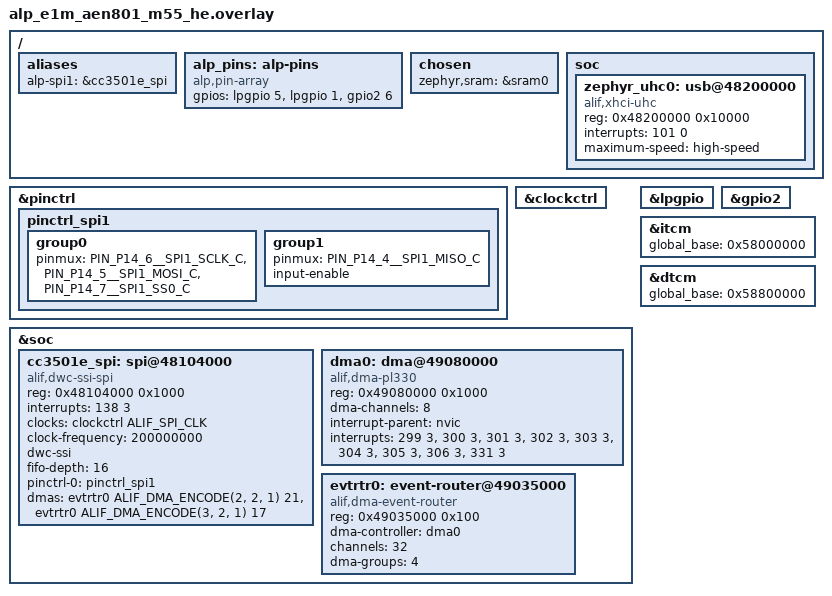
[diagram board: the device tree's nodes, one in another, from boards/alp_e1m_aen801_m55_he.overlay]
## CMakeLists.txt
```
# Copyright (c) 2026 Alp Lab AB
# SPDX-License-Identifier: Apache-2.0
cmake_minimum_required(VERSION 3.20.0)
find_package(Zephyr REQUIRED HINTS $ENV{ZEPHYR_BASE})
project(aen_usb_firstlight)
target_sources(app PRIVATE src/main.c src/cc3501e_bridge.c)
```

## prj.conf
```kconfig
CONFIG_ALP_SDK=y
CONFIG_MAIN_STACK_SIZE=4096
CONFIG_UHC_DRIVER=y
CONFIG_DCACHE=n
CONFIG_SPI=y
CONFIG_GPIO=y
CONFIG_ALP_SDK_CHIP_CC3501E=y
CONFIG_DMA=y
CONFIG_DMA_PL330_ALIF=y
CONFIG_DMA_ALIF_EVENT_ROUTER=y
CONFIG_SPI_DW_ALIF_USE_DMA=y
CONFIG_SPI_DW_ALIF_DMA_MIN_LEN=64
```

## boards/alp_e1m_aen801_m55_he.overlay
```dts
/*
 * Copyright (c) 2026 Alp Lab AB
 * SPDX-License-Identifier: Apache-2.0
 *
 * Inter-chip wiring for the CC3501E bring-up on the E1M-AEN801 (Alif
 * Ensemble E8, M55-HE).  Declares the SoM-internal Alif<->CC3501E link:
 * the SPI1 master bus + the two host-driven control nets, all from
 * metadata/e1m_modules/aen/inter-chip.tsv:
 *
 *   SPI1.SCK  P14_6   SPI1.MOSI P14_5   SPI1.MISO P14_4   (-> CC3501E GPIO_27/28/29)
 *   WIFI_EN   P15_5 (lpgpio 5)          E_WIFI.NRST P15_1_FLEX (lpgpio 1)
 *
 * "P15" is the Alif low-power GPIO island (lpgpio @ 0x42002000); the
 * _FLEX pads are its pins.  P14 is a main-domain port used here purely as
 * the SPI1 function via pinctrl, so no gpio14 controller node is needed.
 *
 * BENCH-UNVERIFIED.  Like the rest of the alp-sdk Alif peripheral layer
 * (zephyr/dts/alif/ensemble_e8_peripherals.dtsi), the addresses/IRQs are
 * transcribed from the Apache-2.0 alifsemi/zephyr_alif fork + the AE822
 * TRM and have NOT been validated on silicon.  The SPI1 pinctrl macros are
 * RESOLVED against zephyr/dt-bindings/pinctrl/alif-ensemble-pinctrl.h
 * (SPI1 on P14_4/5/6 = alt-2, the `_C` suffix) and the LP-GPIO mux is the
 * reset default (alt-0 = LPGPIO); the one remaining genuine unknown is the
 * SPI1 IRQ number (upstream Zephyr declares no SPI node, so it is not in
 * the build tree) -- confirm it against the AE822 TRM before relying on
 * the interrupt-driven path on silicon.
 */

#include <zephyr/dt-bindings/pinctrl/alif-ensemble-pinctrl.h>
#include <zephyr/dt-bindings/gpio/gpio.h>
#include <zephyr/dt-bindings/dma/alif_dma_event_router.h>

&pinctrl {
	/*
	 * SPI1 master on P14_6 (SCK) / P14_5 (MOSI) / P14_4 (MISO).
	 *
	 * RESOLVED against alif-ensemble-pinctrl.h: the SPI1 functions on these
	 * three pads are alt-2, named with the `_C` suffix
	 * (PIN_P14_6__SPI1_SCLK_C = ALIF_PINMUX(14, 6, 2), etc.).  input-enable
	 * on MISO so the pad can sense the slave's drive (the same read-enable
	 * requirement the I2C pads need on this SoC).
	 */
	pinctrl_spi1: pinctrl_spi1 {
		group0 {
			/* Hardware SS0 chip-select (P14_7 = SPI1_SS0_C) -- dwc-ssi master
			 * drives SS0 per transfer to frame the CC3501E slave. */
			pinmux = <PIN_P14_6__SPI1_SCLK_C>, <PIN_P14_5__SPI1_MOSI_C>,
				 <PIN_P14_7__SPI1_SS0_C>;
		};
		group1 {
			pinmux = <PIN_P14_4__SPI1_MISO_C>;
			input-enable;
		};
	};
};

/*
 * DWC_ssi SPI1 (AHB) -- the on-SoM CC3501E inter-chip link.  Deliberately
 * NOT in ensemble_e8_peripherals.dtsi (that dtsi declares only the
 * customer-facing edge SPI0); this is the SoM-internal Wi-Fi link, so it
 * lives in the consuming app's overlay.  Same driver + flags as spi0
 * (compatible "alif,dwc-ssi-spi", dwc-ssi layout, fifo-depth 16,
 * frequency-only ALIF_SPI_CLK).
 *
 * reg 0x48104000 = SPI1 base (spi0 is 0x48103000, +0x1000/instance).
 * BENCH-TBD: interrupts = <138 3> follows the consecutive pattern from
 * spi0's IRQ 137 -- confirm SPI1_IRQ against the fork's e1.dtsi / TRM.
 *
 * No cs-gpios / HW-SS: this rev runs CS-less 3-wire (the host driver
 * clocks fixed-count lockstep transfers; see chips/cc3501e/cc3501e.c).
 */
&clockctrl {
	status = "okay";
};

&soc {
	cc3501e_spi: spi@48104000 {
		compatible = "alif,dwc-ssi-spi";
		#address-cells = <1>;
		#size-cells = <0>;
		reg = <0x48104000 0x1000>;
		interrupts = <138 3>;          /* BENCH-TBD: confirm SPI1 IRQ */
		clocks = <&clockctrl ALIF_SPI_CLK>;
		/*
		 * ROOT-CAUSE FIX 2026-06-16: spi_dw_alif's configure takes the
		 * clock-control path when no clock-frequency is set, and that path
		 * fails (-EINVAL) for the gateless dummy ALIF_SPI_CLK -> every
		 * transceive returned ALP_ERR_INVAL with zero SCLK (witness fail_step=1,
		 * zerr=-EINVAL). Providing the SSI input clock here makes the driver
		 * use it directly and skip the failing clock-control path. SYST_HCLK =
		 * AHB = 400 MHz (E8 HWRM); BAUDR = 400M/freq_hz (=50 for an 8 MHz SCLK).
		 */
		clock-frequency = <200000000>; /* real SSI functional clock (was mis-set 400M; proven via BAUDR scaling) */
		dwc-ssi;
		fifo-depth = <16>;
		pinctrl-0 = <&pinctrl_spi1>;
		pinctrl-names = "default";
		status = "okay";
	};
};

/*
 * Enable the LP GPIO island so WIFI_EN (P15_5) and E_WIFI.NRST
 * (P15_1_FLEX) are drivable as outputs.  gpio_dw needs no clocks/pinctrl
 * on the controller, and the pad->GPIO mux needs no pinctrl group either:
 * RESOLVED against alif-ensemble-pinctrl.h -- P15_1/P15_5 function 0 (the
 * reset default) IS LPGPIO (PIN_P15_x__LPGPIO = ALIF_PINMUX(15, x, 0)).
 */
&lpgpio {
	status = "okay";
};

/*
 * gpio2 for the host-IRQ/READY input (CC35 GPIO17 -> Alif P2_6, alp_pins[2]).
 * P2_6's reset-default mux is function 0 = GPIO (PIN_P2_6__GPIO), so no pinctrl
 * group is needed; gpio_dw defaults the pin to input, which the app confirms via
 * alp_gpio_configure(INPUT).  The READY line lets the host gate reply phases on
 * the slave's actual re-arm instead of a fixed settle gap. */
&gpio2 {
	status = "okay";
};

/*
 * Host-side peripheral DMA for continuous SPI streams over the CC3501E bridge.
 * SPI1 is a MAIN-domain peripheral, so per the AE822 DFP soc_dma_map (SPI1_DMA=0,
 * group 2, TX req 21 / RX req 17) it routes through the SYSTOP DMA0 via its event
 * router evtrtr0 (4 groups -> group 2 valid) -- NOT the M55-HE-local DMA2/evtrtr2
 * (1 group, for LP peripherals; wiring SPI1 there leaves the channel Waiting-For-
 * Peripheral forever -- SPI1's request line isn't on the HE router).  DMA0's clock
 * is SYSTOP (already on -- the app drives SPI1/GPIO in the same region); its
 * PL330 boot-manager security latch (CLKCTRL_PER_MST) is in dma_alif_boot_latch.c.
 * The fork PL330 driver statically allocates the per-channel ucode + remaps it via
 * local_to_global(), so no external `microcode` prop is needed.  IRQs 299..306 =
 * the 8 DMA0 channel-done lines, 331 = abort (AE822 DFP rtss_he).
 */
&soc {
	dma0: dma@49080000 {
		compatible = "alif,dma-pl330";
		reg = <0x49080000 0x1000>;
		#dma-cells = <2>;
		dma-channels = <8>;
		interrupt-parent = <&nvic>;
		interrupts = <299 3>, <300 3>, <301 3>, <302 3>, <303 3>,
			     <304 3>, <305 3>, <306 3>, <331 3>;
		interrupt-names = "channel0", "channel1", "channel2", "channel3",
				  "channel4", "channel5", "channel6", "channel7", "abort";
		status = "okay";
	};

	evtrtr0: event-router@49035000 {
		compatible = "alif,dma-event-router";
		reg = <0x49035000 0x100>;
		dma-controller = <&dma0>;
		channels = <32>;
		dma-groups = <4>;  /* SYSTOP router: 4 ACK_TYPE groups (0-3); SPI1 uses group 2 */
		#dma-cells = <2>;
		status = "okay";
	};
};

/*
 * Route the bridge SPI1 through evtrtr0 to DMA0.  Cell encoding
 * (ALIF_DMA_ENCODE(channel, dma_group, handshake), periph_req):
 *   TX = PL330 ch2, evtrtr group 2, handshake on, SPI1 TX periph req 21
 *   RX = PL330 ch3, evtrtr group 2, handshake on, SPI1 RX periph req 17
 * (AE822 DFP soc_dma_map.h: SPI1 group 2, TX 21 / RX 17.)
 */
&cc3501e_spi {
	dmas = <&evtrtr0 ALIF_DMA_ENCODE(2, 2, 1) 21>,
	       <&evtrtr0 ALIF_DMA_ENCODE(3, 2, 1) 17>;
	dma-names = "txdma", "rxdma";
};

/ {
	aliases {
		/* bus_id 1 in alp_spi_open() -> this controller. */
		alp-spi1 = &cc3501e_spi;
	};

	/*
	 * Compact 2-entry control array for the SoM-internal CC3501E nets, in
	 * the order the app's CC3501E_PIN_* indices expect.  These are NOT E1M
	 * edge pads, so this bring-up app intentionally does NOT use the
	 * 52-slot positional E1M map; a production board file appends such
	 * SoM-internal control nets after the E1M pad slots.
	 */
	alp_pins: alp-pins {
		compatible = "alp,pin-array";
		gpios = <&lpgpio 5 GPIO_ACTIVE_HIGH>,   /* [0] WIFI_EN     (P15_5)      */
			<&lpgpio 1 GPIO_ACTIVE_HIGH>,   /* [1] E_WIFI.NRST (P15_1_FLEX) */
			<&gpio2 6 GPIO_ACTIVE_HIGH>;    /* [2] host-IRQ/READY (P2_6 <- CC35 GPIO17) */
	};
};

/*
 * Global-bus aliases of the M55-HE TCMs, needed by hal_alif soc_memory_map.h
 * local_to_global() -- the PL330 (AXI master) reaches TCM-resident buffers only
 * via these global windows.  Values from the AE822 M55-HE map (sdk-alif fork
 * ensemble_rtss_he.dtsi): ITCM 0x0->0x58000000, DTCM 0x20000000->0x58800000.
 * (DMA stream buffers still belong in SRAM0 0x02000000, which is already global
 * -> local_to_global() returns it unchanged.)
 */
&itcm {
	global_base = <0x58000000>;
};
&dtcm {
	global_base = <0x58800000>;
};

/* --- USB host (xHCI @0x48200000) for aen-usb-firstlight --- */
/ {
	chosen { zephyr,sram = &sram0; };
	soc {
		zephyr_uhc0: usb@48200000 {
			compatible = "alif,xhci-uhc";
			reg = <0x48200000 0x10000>;
			interrupts = <101 0>;
			maximum-speed = "high-speed";
			status = "okay";
		};
	};
};
```

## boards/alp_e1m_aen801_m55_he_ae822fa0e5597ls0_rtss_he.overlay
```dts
/*
 * Copyright (c) 2026 Alp Lab AB
 * SPDX-License-Identifier: Apache-2.0
 *
 * Inter-chip wiring for the CC3501E bring-up on the E1M-AEN801 (Alif
 * Ensemble E8, M55-HE).  Declares the SoM-internal Alif<->CC3501E link:
 * the SPI1 master bus + the two host-driven control nets, all from
 * metadata/e1m_modules/aen/inter-chip.tsv:
 *
 *   SPI1.SCK  P14_6   SPI1.MOSI P14_5   SPI1.MISO P14_4   (-> CC3501E GPIO_27/28/29)
 *   WIFI_EN   P15_5 (lpgpio 5)          E_WIFI.NRST P15_1_FLEX (lpgpio 1)
 *
 * "P15" is the Alif low-power GPIO island (lpgpio @ 0x42002000); the
 * _FLEX pads are its pins.  P14 is a main-domain port used here purely as
 * the SPI1 function via pinctrl, so no gpio14 controller node is needed.
 *
 * BENCH-UNVERIFIED.  Like the rest of the alp-sdk Alif peripheral layer
 * (zephyr/dts/alif/ensemble_e8_peripherals.dtsi), the addresses/IRQs are
 * transcribed from the Apache-2.0 alifsemi/zephyr_alif fork + the AE822
 * TRM and have NOT been validated on silicon.  The SPI1 pinctrl macros are
 * RESOLVED against zephyr/dt-bindings/pinctrl/alif-ensemble-pinctrl.h
 * (SPI1 on P14_4/5/6 = alt-2, the `_C` suffix) and the LP-GPIO mux is the
 * reset default (alt-0 = LPGPIO); the one remaining genuine unknown is the
 * SPI1 IRQ number (upstream Zephyr declares no SPI node, so it is not in
 * the build tree) -- confirm it against the AE822 TRM before relying on
 * the interrupt-driven path on silicon.
 */

#include <zephyr/dt-bindings/pinctrl/alif-ensemble-pinctrl.h>
#include <zephyr/dt-bindings/gpio/gpio.h>
#include <zephyr/dt-bindings/dma/alif_dma_event_router.h>

&pinctrl {
	/*
	 * SPI1 master on P14_6 (SCK) / P14_5 (MOSI) / P14_4 (MISO).
	 *
	 * RESOLVED against alif-ensemble-pinctrl.h: the SPI1 functions on these
	 * three pads are alt-2, named with the `_C` suffix
	 * (PIN_P14_6__SPI1_SCLK_C = ALIF_PINMUX(14, 6, 2), etc.).  input-enable
	 * on MISO so the pad can sense the slave's drive (the same read-enable
	 * requirement the I2C pads need on this SoC).
	 */
	pinctrl_spi1: pinctrl_spi1 {
		group0 {
			/* Hardware SS0 chip-select (P14_7 = SPI1_SS0_C) -- dwc-ssi master
			 * drives SS0 per transfer to frame the CC3501E slave. */
			pinmux = <PIN_P14_6__SPI1_SCLK_C>, <PIN_P14_5__SPI1_MOSI_C>,
				 <PIN_P14_7__SPI1_SS0_C>;
		};
		group1 {
			pinmux = <PIN_P14_4__SPI1_MISO_C>;
			input-enable;
		};
	};
};

/*
 * DWC_ssi SPI1 (AHB) -- the on-SoM CC3501E inter-chip link.  Deliberately
 * NOT in ensemble_e8_peripherals.dtsi (that dtsi declares only the
 * customer-facing edge SPI0); this is the SoM-internal Wi-Fi link, so it
 * lives in the consuming app's overlay.  Same driver + flags as spi0
 * (compatible "alif,dwc-ssi-spi", dwc-ssi layout, fifo-depth 16,
 * frequency-only ALIF_SPI_CLK).
 *
 * reg 0x48104000 = SPI1 base (spi0 is 0x48103000, +0x1000/instance).
 * BENCH-TBD: interrupts = <138 3> follows the consecutive pattern from
 * spi0's IRQ 137 -- confirm SPI1_IRQ against the fork's e1.dtsi / TRM.
 *
 * No cs-gpios: P14_7 is muxed as SPI1_SS0_C above and the dwc-ssi peripheral
 * drives hardware SS0 per transfer.  The host opens ALP_SPI_NO_CS so no GPIO CS
 * is installed, allowing the SPI driver to use its hardware slave-select path.
 */
&clockctrl {
	status = "okay";
};

&soc {
	cc3501e_spi: spi@48104000 {
		compatible = "alif,dwc-ssi-spi";
		#address-cells = <1>;
		#size-cells = <0>;
		reg = <0x48104000 0x1000>;
		interrupts = <138 3>;          /* BENCH-TBD: confirm SPI1 IRQ */
		clocks = <&clockctrl ALIF_SPI_CLK>;
		/*
		 * ROOT-CAUSE FIX 2026-06-16: spi_dw_alif's configure takes the
		 * clock-control path when no clock-frequency is set, and that path
		 * fails (-EINVAL) for the gateless dummy ALIF_SPI_CLK -> every
		 * transceive returned ALP_ERR_INVAL with zero SCLK (witness fail_step=1,
		 * zerr=-EINVAL). Providing the SSI input clock here makes the driver
		 * use it directly and skip the failing clock-control path. The SSI
		 * functional clock is 200 MHz (E8 HWRM); BAUDR = clk/freq_hz.
		 */
		clock-frequency = <200000000>; /* real SSI functional clock (was mis-set 400M; proven via BAUDR scaling) */
		dwc-ssi;
		fifo-depth = <16>;
		pinctrl-0 = <&pinctrl_spi1>;
		pinctrl-names = "default";
		status = "okay";
	};
};

/*
 * Enable the LP GPIO island so WIFI_EN (P15_5) and E_WIFI.NRST
 * (P15_1_FLEX) are drivable as outputs.  gpio_dw needs no clocks/pinctrl
 * on the controller, and the pad->GPIO mux needs no pinctrl group either:
 * RESOLVED against alif-ensemble-pinctrl.h -- P15_1/P15_5 function 0 (the
 * reset default) IS LPGPIO (PIN_P15_x__LPGPIO = ALIF_PINMUX(15, x, 0)).
 */
&lpgpio {
	status = "okay";
};

/* P2_6 (E1M AH7 / I2S1_SCLK) is NOT the CC3501E READY net on the R2 module this
 * bridge targets -- it is E1M pad AH7 / I2S1_SCLK, which the E1M EVK carrier
 * repurposes as the Arduino header's CK_RST (metadata/boards/e1m-evk.yaml);
 * the real READY net lands on E1M pad G3 / IO16 instead
 * (metadata/e1m_modules/aen/from-cc3501e.tsv). This app therefore does not
 * enable &gpio2 or claim P2_6 as READY -- see src/cc3501e_bridge.c and
 * chips/cc3501e/cc3501e_core.c's cc3501e_reply_gate() comment. A board (or a
 * hand-reworked r1 unit) that genuinely wires GPIO17 to P2_6 can opt back
 * in: enable &gpio2, add a pinctrl group that enables P2_6's INPUT BUFFER --
 * reset-default mux already IS GPIO, but GPIO function alone does not enable
 * the input path; skip that group and cc3501e_reply_gate()'s read comes back
 * a constant 0 forever, indistinguishable from a stuck-LOW pad -- add an
 * alp_pins entry for it, and set fw->ready_pin in cc3501e_bridge_bringup(). */

/*
 * Host-side peripheral DMA for continuous SPI streams over the CC3501E bridge.
 * SPI1 is a MAIN-domain peripheral, so per the AE822 DFP soc_dma_map (SPI1_DMA=0,
 * group 2, TX req 21 / RX req 17) it routes through the SYSTOP DMA0 via its event
 * router evtrtr0 (4 groups -> group 2 valid) -- NOT the M55-HE-local DMA2/evtrtr2
 * (1 group, for LP peripherals; wiring SPI1 there leaves the channel Waiting-For-
 * Peripheral forever -- SPI1's request line isn't on the HE router).  DMA0's clock
 * is SYSTOP (already on -- the app drives SPI1/GPIO in the same region); its
 * PL330 boot-manager security latch (CLKCTRL_PER_MST) is in dma_alif_boot_latch.c.
 * The fork PL330 driver statically allocates the per-channel ucode + remaps it via
 * local_to_global(), so no external `microcode` prop is needed.
 *
 * dma0 + evtrtr0 are now declared in ensemble_e8_peripherals.dtsi (disabled
 * by default, alp-sdk issue #1815); this overlay only enables them.
 */
&dma0 {
	status = "okay";
};

&evtrtr0 {
	status = "okay";
};

/*
 * Route the bridge SPI1 through evtrtr0 to DMA0.  Cell encoding
 * (ALIF_DMA_ENCODE(channel, dma_group, handshake), periph_req):
 *   TX = PL330 ch2, evtrtr group 2, handshake on, SPI1 TX periph req 21
 *   RX = PL330 ch3, evtrtr group 2, handshake on, SPI1 RX periph req 17
 * (AE822 DFP soc_dma_map.h: SPI1 group 2, TX 21 / RX 17.)
 */
&cc3501e_spi {
	dmas = <&evtrtr0 ALIF_DMA_ENCODE(2, 2, 1) 21>,
	       <&evtrtr0 ALIF_DMA_ENCODE(3, 2, 1) 17>;
	dma-names = "txdma", "rxdma";
};

/ {
	aliases {
		/* bus_id 1 in alp_spi_open() -> this controller. */
		alp-spi1 = &cc3501e_spi;
	};

	/*
	 * Compact 2-entry control array for the SoM-internal CC3501E control
	 * nets, in the order the app's CC3501E_PIN_* indices expect.  These are
	 * NOT E1M edge pads, so this bring-up app intentionally does NOT use the
	 * 52-slot positional E1M map; a production board file appends such
	 * SoM-internal control nets after the E1M pad slots.  No READY entry
	 * here -- see the P2_6 comment above &gpio2's removal further up.
	 */
	alp_pins: alp-pins {
		compatible = "alp,pin-array";
		gpios = <&lpgpio 5 GPIO_ACTIVE_HIGH>, /* [0] WIFI_EN     (P15_5)      */
			<&lpgpio 1 GPIO_ACTIVE_HIGH>; /* [1] E_WIFI.NRST (P15_1_FLEX) */
	};
};

/*
 * Global-bus aliases of the M55-HE TCMs, needed by hal_alif soc_memory_map.h
 * local_to_global() -- the PL330 (AXI master) reaches TCM-resident buffers only
 * via these global windows.  Values from the AE822 M55-HE map (sdk-alif fork
 * ensemble_rtss_he.dtsi): ITCM 0x0->0x58000000, DTCM 0x20000000->0x58800000.
 * (DMA stream buffers still belong in SRAM0 0x02000000, which is already global
 * -> local_to_global() returns it unchanged.)
 */
&itcm {
	global_base = <0x58000000>;
};
&dtcm {
	global_base = <0x58800000>;
};

/* --- USB host (xHCI @0x48200000) for aen-usb-firstlight --- */
/ {
	chosen { zephyr,sram = &sram0; };
	soc {
		zephyr_uhc0: usb@48200000 {
			compatible = "alif,xhci-uhc";
			reg = <0x48200000 0x10000>;
			interrupts = <101 0>;
			maximum-speed = "high-speed";
			status = "okay";
		};
	};
};
```

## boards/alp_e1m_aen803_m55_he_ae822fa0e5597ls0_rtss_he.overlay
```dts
/*
 * Copyright (c) 2026 Alp Lab AB
 * SPDX-License-Identifier: Apache-2.0
 *
 * Inter-chip wiring for the CC3501E bring-up on the E1M-AEN803 (Alif
 * Ensemble E8, M55-HE).  Declares the SoM-internal Alif<->CC3501E link:
 * the SPI1 master bus + the two host-driven control nets, all from
 * metadata/e1m_modules/aen/inter-chip.tsv:
 *
 *   SPI1.SCK  P14_6   SPI1.MOSI P14_5   SPI1.MISO P14_4   (-> CC3501E GPIO_27/28/29)
 *   WIFI_EN   P15_5 (lpgpio 5)          E_WIFI.NRST P15_1_FLEX (lpgpio 1)
 *
 * "P15" is the Alif low-power GPIO island (lpgpio @ 0x42002000); the
 * _FLEX pads are its pins.  P14 is a main-domain port used here purely as
 * the SPI1 function via pinctrl, so no gpio14 controller node is needed.
 *
 * BENCH-UNVERIFIED.  Like the rest of the alp-sdk Alif peripheral layer
 * (zephyr/dts/alif/ensemble_e8_peripherals.dtsi), the addresses/IRQs are
 * transcribed from the Apache-2.0 alifsemi/zephyr_alif fork + the AE822
 * TRM and have NOT been validated on silicon.  The SPI1 pinctrl macros are
 * RESOLVED against zephyr/dt-bindings/pinctrl/alif-ensemble-pinctrl.h
 * (SPI1 on P14_4/5/6 = alt-2, the `_C` suffix) and the LP-GPIO mux is the
 * reset default (alt-0 = LPGPIO); the one remaining genuine unknown is the
 * SPI1 IRQ number (upstream Zephyr declares no SPI node, so it is not in
 * the build tree) -- confirm it against the AE822 TRM before relying on
 * the interrupt-driven path on silicon.
 */

#include <zephyr/dt-bindings/pinctrl/alif-ensemble-pinctrl.h>
#include <zephyr/dt-bindings/gpio/gpio.h>
#include <zephyr/dt-bindings/dma/alif_dma_event_router.h>

&pinctrl {
	/*
	 * SPI1 master on P14_6 (SCK) / P14_5 (MOSI) / P14_4 (MISO).
	 *
	 * RESOLVED against alif-ensemble-pinctrl.h: the SPI1 functions on these
	 * three pads are alt-2, named with the `_C` suffix
	 * (PIN_P14_6__SPI1_SCLK_C = ALIF_PINMUX(14, 6, 2), etc.).  input-enable
	 * on MISO so the pad can sense the slave's drive (the same read-enable
	 * requirement the I2C pads need on this SoC).
	 */
	pinctrl_spi1: pinctrl_spi1 {
		group0 {
			/* Hardware SS0 chip-select (P14_7 = SPI1_SS0_C) -- dwc-ssi master
			 * drives SS0 per transfer to frame the CC3501E slave. */
			pinmux = <PIN_P14_6__SPI1_SCLK_C>, <PIN_P14_5__SPI1_MOSI_C>,
				 <PIN_P14_7__SPI1_SS0_C>;
		};
		group1 {
			pinmux = <PIN_P14_4__SPI1_MISO_C>;
			input-enable;
		};
	};
};

/*
 * DWC_ssi SPI1 (AHB) -- the on-SoM CC3501E inter-chip link.  Deliberately
 * NOT in ensemble_e8_peripherals.dtsi (that dtsi declares only the
 * customer-facing edge SPI0); this is the SoM-internal Wi-Fi link, so it
 * lives in the consuming app's overlay.  Same driver + flags as spi0
 * (compatible "alif,dwc-ssi-spi", dwc-ssi layout, fifo-depth 16,
 * frequency-only ALIF_SPI_CLK).
 *
 * reg 0x48104000 = SPI1 base (spi0 is 0x48103000, +0x1000/instance).
 * BENCH-TBD: interrupts = <138 3> follows the consecutive pattern from
 * spi0's IRQ 137 -- confirm SPI1_IRQ against the fork's e1.dtsi / TRM.
 *
 * No cs-gpios: P14_7 is muxed as SPI1_SS0_C above and the dwc-ssi peripheral
 * drives hardware SS0 per transfer.  The host opens ALP_SPI_NO_CS so no GPIO CS
 * is installed, allowing the SPI driver to use its hardware slave-select path.
 */
&clockctrl {
	status = "okay";
};

&soc {
	cc3501e_spi: spi@48104000 {
		compatible = "alif,dwc-ssi-spi";
		#address-cells = <1>;
		#size-cells = <0>;
		reg = <0x48104000 0x1000>;
		interrupts = <138 3>;          /* BENCH-TBD: confirm SPI1 IRQ */
		clocks = <&clockctrl ALIF_SPI_CLK>;
		/*
		 * ROOT-CAUSE FIX 2026-06-16: spi_dw_alif's configure takes the
		 * clock-control path when no clock-frequency is set, and that path
		 * fails (-EINVAL) for the gateless dummy ALIF_SPI_CLK -> every
		 * transceive returned ALP_ERR_INVAL with zero SCLK (witness fail_step=1,
		 * zerr=-EINVAL). Providing the SSI input clock here makes the driver
		 * use it directly and skip the failing clock-control path. The SSI
		 * functional clock is 200 MHz (E8 HWRM); BAUDR = clk/freq_hz.
		 */
		clock-frequency = <200000000>; /* real SSI functional clock (was mis-set 400M; proven via BAUDR scaling) */
		dwc-ssi;
		fifo-depth = <16>;
		pinctrl-0 = <&pinctrl_spi1>;
		pinctrl-names = "default";
		status = "okay";
	};
};

/*
 * Enable the LP GPIO island so WIFI_EN (P15_5) and E_WIFI.NRST
 * (P15_1_FLEX) are drivable as outputs.  gpio_dw needs no clocks/pinctrl
 * on the controller, and the pad->GPIO mux needs no pinctrl group either:
 * RESOLVED against alif-ensemble-pinctrl.h -- P15_1/P15_5 function 0 (the
 * reset default) IS LPGPIO (PIN_P15_x__LPGPIO = ALIF_PINMUX(15, x, 0)).
 */
&lpgpio {
	status = "okay";
};

/* P2_6 (E1M AH7 / I2S1_SCLK) is NOT the CC3501E READY net on the R2 module this
 * bridge targets -- it is E1M pad AH7 / I2S1_SCLK, which the E1M EVK carrier
 * repurposes as the Arduino header's CK_RST (metadata/boards/e1m-evk.yaml);
 * the real READY net lands on E1M pad G3 / IO16 instead
 * (metadata/e1m_modules/aen/from-cc3501e.tsv). This app therefore does not
 * enable &gpio2 or claim P2_6 as READY -- see src/cc3501e_bridge.c and
 * chips/cc3501e/cc3501e_core.c's cc3501e_reply_gate() comment. A board (or a
 * hand-reworked r1 unit) that genuinely wires GPIO17 to P2_6 can opt back
 * in: enable &gpio2, add a pinctrl group that enables P2_6's INPUT BUFFER --
 * reset-default mux already IS GPIO, but GPIO function alone does not enable
 * the input path; skip that group and cc3501e_reply_gate()'s read comes back
 * a constant 0 forever, indistinguishable from a stuck-LOW pad -- add an
 * alp_pins entry for it, and set fw->ready_pin in cc3501e_bridge_bringup(). */

/*
 * Host-side peripheral DMA for continuous SPI streams over the CC3501E bridge.
 * SPI1 is a MAIN-domain peripheral, so per the AE822 DFP soc_dma_map (SPI1_DMA=0,
 * group 2, TX req 21 / RX req 17) it routes through the SYSTOP DMA0 via its event
 * router evtrtr0 (4 groups -> group 2 valid) -- NOT the M55-HE-local DMA2/evtrtr2
 * (1 group, for LP peripherals; wiring SPI1 there leaves the channel Waiting-For-
 * Peripheral forever -- SPI1's request line isn't on the HE router).  DMA0's clock
 * is SYSTOP (already on -- the app drives SPI1/GPIO in the same region); its
 * PL330 boot-manager security latch (CLKCTRL_PER_MST) is in dma_alif_boot_latch.c.
 * The fork PL330 driver statically allocates the per-channel ucode + remaps it via
 * local_to_global(), so no external `microcode` prop is needed.
 *
 * dma0 + evtrtr0 are now declared in ensemble_e8_peripherals.dtsi (disabled
 * by default, alp-sdk issue #1815); this overlay only enables them.
 */
&dma0 {
	status = "okay";
};

&evtrtr0 {
	status = "okay";
};

/*
 * Route the bridge SPI1 through evtrtr0 to DMA0.  Cell encoding
 * (ALIF_DMA_ENCODE(channel, dma_group, handshake), periph_req):
 *   TX = PL330 ch2, evtrtr group 2, handshake on, SPI1 TX periph req 21
 *   RX = PL330 ch3, evtrtr group 2, handshake on, SPI1 RX periph req 17
 * (AE822 DFP soc_dma_map.h: SPI1 group 2, TX 21 / RX 17.)
 */
&cc3501e_spi {
	dmas = <&evtrtr0 ALIF_DMA_ENCODE(2, 2, 1) 21>,
	       <&evtrtr0 ALIF_DMA_ENCODE(3, 2, 1) 17>;
	dma-names = "txdma", "rxdma";
};

/ {
	aliases {
		/* bus_id 1 in alp_spi_open() -> this controller. */
		alp-spi1 = &cc3501e_spi;
	};

	/*
	 * Compact 2-entry control array for the SoM-internal CC3501E control
	 * nets, in the order the app's CC3501E_PIN_* indices expect.  These are
	 * NOT E1M edge pads, so this bring-up app intentionally does NOT use the
	 * 52-slot positional E1M map; a production board file appends such
	 * SoM-internal control nets after the E1M pad slots.  No READY entry
	 * here -- see the P2_6 comment above &gpio2's removal further up.
	 */
	alp_pins: alp-pins {
		compatible = "alp,pin-array";
		gpios = <&lpgpio 5 GPIO_ACTIVE_HIGH>, /* [0] WIFI_EN     (P15_5)      */
			<&lpgpio 1 GPIO_ACTIVE_HIGH>; /* [1] E_WIFI.NRST (P15_1_FLEX) */
	};
};

/*
 * Global-bus aliases of the M55-HE TCMs, needed by hal_alif soc_memory_map.h
 * local_to_global() -- the PL330 (AXI master) reaches TCM-resident buffers only
 * via these global windows.  Values from the AE822 M55-HE map (sdk-alif fork
 * ensemble_rtss_he.dtsi): ITCM 0x0->0x58000000, DTCM 0x20000000->0x58800000.
 * (DMA stream buffers still belong in SRAM0 0x02000000, which is already global
 * -> local_to_global() returns it unchanged.)
 */
&itcm {
	global_base = <0x58000000>;
};
&dtcm {
	global_base = <0x58800000>;
};

/* --- USB host (xHCI @0x48200000) for aen-usb-firstlight --- */
/ {
	chosen { zephyr,sram = &sram0; };
	soc {
		zephyr_uhc0: usb@48200000 {
			compatible = "alif,xhci-uhc";
			reg = <0x48200000 0x10000>;
			interrupts = <101 0>;
			maximum-speed = "high-speed";
			status = "okay";
		};
	};
};
```

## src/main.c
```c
/*
 * Copyright (c) 2026 Alp Lab AB
 * SPDX-License-Identifier: Apache-2.0
 *
 * xHCI USB host enumeration on the E1M-AEN801, driving the board USB2_SELECT mux.
 *
 * The E8 has one USB (USB2); its D+/D- pass through mux U47 to the USB-C
 * connector (CON_USB2 = J13).  U47's select `USB2_SELECT` = E1M IO11 = CC3501E
 * GPIO pad 2 (a coprocessor GPIO).  So before the E8 xHCI can see a device on
 * J13, the CC3501E must drive that GPIO to route the mux.  We bring up the
 * CC3501E bridge, drive GPIO pad 2 over the SPI GPIO-proxy, then run the host:
 * uhc_init (DWC3 + xHCI first light) + uhc_enable (run + rings + Enable Slot +
 * port reset + Address Device + EP0 GET_DESCRIPTOR).  Device descriptor lands in
 * the driver's g_..._data_0.fl snapshot.  USB_ID = 0 (P2 jumper) sets host role.
 */
#include <zephyr/kernel.h>
#include <zephyr/device.h>
#include <zephyr/devicetree.h>
#include <zephyr/drivers/usb/uhc.h>
#include <zephyr/sys/printk.h>

#include <alp/chips/cc3501e.h>
#include "cc3501e_bridge.h"

#ifndef USB2_SEL_LVL
#define USB2_SEL_LVL 1
#endif
#define CC3501E_USB2_SELECT_PAD 2u

/* SWD-readable witness for the CC3501E mux-drive (magic "USMX"): lets a bench
 * engineer confirm the mux was actually routed by reading this struct out of
 * RAM over the debug probe, without needing a UART attached. bringup is the
 * cc3501e_bridge_bringup() alp_status_t; gpio_cfg/gpio_wr are the GPIO-proxy
 * configure/write return codes for the mux-select pad; level is the drive
 * level requested (USB2_SEL_LVL). __attribute__((used)) keeps it in the
 * image even though nothing but SWD reads it. */
volatile struct {
	uint32_t magic;
	int32_t  bringup;
	int32_t  gpio_cfg;
	int32_t  gpio_wr;
	int32_t  level;
} g_usbmux __attribute__((used)) = { .magic = 0x55534d58u, .level = USB2_SEL_LVL };

/* uhc_init() requires an event callback but this example polls the
 * synchronous return codes of uhc_init/uhc_enable and the driver's own data
 * snapshot below instead of reacting to async UHC events, so the callback
 * is intentionally a no-op stub. */
static int fl_cb(const struct device *dev, const struct uhc_event *const event)
{
	ARG_UNUSED(dev);
	ARG_UNUSED(event);
	return 0;
}

int main(void)
{
	static cc3501e_t fw;

	printk("=== AEN801 xHCI USB host: CC3501E USB2_SELECT mux + enumerate ===\n");

	/* 1. Bring up the CC3501E bridge and route the USB2_SELECT mux to J13. */
	alp_status_t bs = cc3501e_bridge_bringup(&fw);

	g_usbmux.bringup = (int32_t)bs;
	if (bs == ALP_OK) {
		g_usbmux.gpio_cfg = (int32_t)cc3501e_gpio_configure(&fw,
		                                                    CC3501E_USB2_SELECT_PAD,
		                                                    ALP_CC3501E_GPIO_DIR_OUTPUT,
		                                                    ALP_CC3501E_GPIO_PULL_NONE,
		                                                    200u);
		g_usbmux.gpio_wr =
		    (int32_t)cc3501e_gpio_write(&fw, CC3501E_USB2_SELECT_PAD, (USB2_SEL_LVL != 0), 200u);
		printk("USB2_SELECT (CC35 GPIO2) cfg=%d wr=%d level=%d\n",
		       g_usbmux.gpio_cfg,
		       g_usbmux.gpio_wr,
		       USB2_SEL_LVL);
		k_busy_wait(200000); /* mux + connect debounce */
	} else {
		printk("WARN: CC3501E link down (%d) -> mux not set\n", (int)bs);
	}

	/* 2. USB host first-light + enumeration. */
	const struct device *dev = DEVICE_DT_GET(DT_NODELABEL(zephyr_uhc0));

	/* device_is_ready() reflects the driver's own init hook (registered at
	 * PRE_KERNEL/POST_KERNEL from the zephyr_uhc0 node in the board overlay);
	 * a false here means the DWC3/xHCI controller failed to attach at boot
	 * (devicetree status/pinctrl issue), not a runtime USB fault. */
	if (!device_is_ready(dev)) {
		printk("RESULT FAIL: uhc device not ready\n");
		return 0;
	}
	/* uhc_init(): DWC3 core reset + PHY bring-up + xHCI event/command/transfer
	 * ring setup -- the controller exists and is addressable, but is not yet
	 * running (no VBUS/port state machine active). */
	if (uhc_init(dev, fl_cb, NULL) != 0) {
		printk("RESULT FAIL: uhc_init/first-light\n");
		return 0;
	}
	/* uhc_enable(): starts the controller (R/S) and drives the full port
	 * enumeration sequence -- port reset, xHCI Enable Slot, Address Device,
	 * then an EP0 GET_DESCRIPTOR -- so a 0 return here means a device was
	 * actually found and answered on J13, not just that USB was armed. */
	int en = uhc_enable(dev);

	printk("RESULT: uhc_enable rc=%d -- enum_stage/descriptor in g_..._data_0.fl\n", en);
	return 0;
}
```
